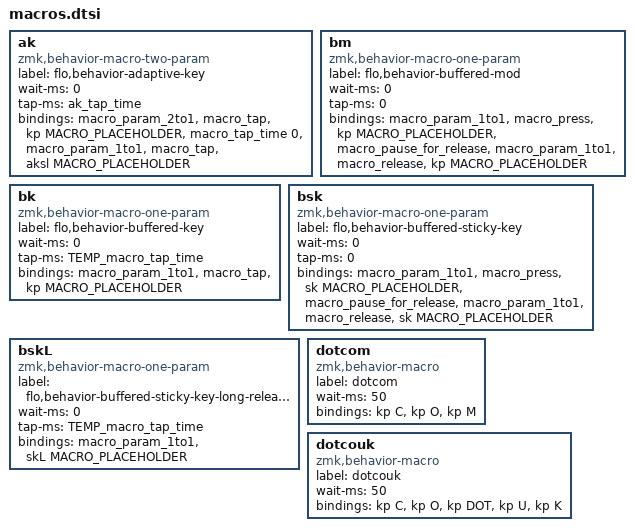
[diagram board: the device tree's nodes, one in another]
REPLACE_CHAR_WITH_BIGRAM(B, B)
REPLACE_CHAR_WITH_BIGRAM(B, M)
REPLACE_CHAR_WITH_BIGRAM(D, G)
REPLACE_CHAR_WITH_BIGRAM(I, F)
REPLACE_CHAR_WITH_BIGRAM(L, B)
REPLACE_CHAR_WITH_BIGRAM(L, G)
REPLACE_CHAR_WITH_BIGRAM(L, K)
REPLACE_CHAR_WITH_BIGRAM(L, M)
REPLACE_CHAR_WITH_BIGRAM(L, N)
REPLACE_CHAR_WITH_BIGRAM(L, V)
REPLACE_CHAR_WITH_BIGRAM(N, J)
REPLACE_CHAR_WITH_BIGRAM(N, K)
REPLACE_CHAR_WITH_BIGRAM(N, M)
REPLACE_CHAR_WITH_BIGRAM(N, V)
REPLACE_CHAR_WITH_BIGRAM(O, B)
REPLACE_CHAR_WITH_BIGRAM(P, M)
REPLACE_CHAR_WITH_BIGRAM(S, B)
REPLACE_CHAR_WITH_BIGRAM(S, P)
REPLACE_CHAR_WITH_BIGRAM(U, B)


ak: ak {
        label = "flo,behavior-adaptive-key";
        compatible = "zmk,behavior-macro-two-param";
        #binding-cells = <2>;
        wait-ms = <0>;
        tap-ms = <ak_tap_time>;
        bindings =
                <&macro_param_2to1>,
                <&macro_tap &kp MACRO_PLACEHOLDER>,

                <&macro_tap_time 0>,

                <&macro_param_1to1>,
                <&macro_tap &aksl MACRO_PLACEHOLDER>;
};


/* // Disable this for now. I don't really need the repeat behavior, and it makes linger keys difficult to hit
bk: bk {
        label = "flo,behavior-buffered-key";
        compatible = "zmk,behavior-macro-one-param";
        #binding-cells = <1>;
        wait-ms = <0>;
        tap-ms = <0>; // Unused
        bindings = 
                <&macro_param_1to1>,
                <&macro_press &kp MACRO_PLACEHOLDER>,

                <&macro_pause_for_release>,

                <&macro_param_1to1>,
                <&macro_release &kp MACRO_PLACEHOLDER>
                ;
};
*/
bm: bm {
        label = "flo,behavior-buffered-mod";
        compatible = "zmk,behavior-macro-one-param";
        #binding-cells = <1>;
        wait-ms = <0>;
        tap-ms = <0>; // Unused
        bindings = 
                <&macro_param_1to1>,
                <&macro_press &kp MACRO_PLACEHOLDER>,

                <&macro_pause_for_release>,

                <&macro_param_1to1>,
                <&macro_release &kp MACRO_PLACEHOLDER>
                ;
};

bk: bk {
        label = "flo,behavior-buffered-key";
        compatible = "zmk,behavior-macro-one-param";
        #binding-cells = <1>;
        wait-ms = <0>;
        tap-ms = <TEMP_macro_tap_time>;
        bindings = 
                <&macro_param_1to1>,
                <&macro_tap &kp MACRO_PLACEHOLDER>
                ;
};

bsk: bsk {
        label = "flo,behavior-buffered-sticky-key";
        compatible = "zmk,behavior-macro-one-param";
        #binding-cells = <1>;
        wait-ms = <0>;
        tap-ms = <0>; // Unused
        bindings = 
                <&macro_param_1to1>,
                <&macro_press &sk MACRO_PLACEHOLDER>,

                <&macro_pause_for_release>,

                <&macro_param_1to1>,
                <&macro_release &sk MACRO_PLACEHOLDER>
                ;
};

bskL: bskL {
        label = "flo,behavior-buffered-sticky-key-long-release";
        compatible = "zmk,behavior-macro-one-param";
        #binding-cells = <1>;
        wait-ms = <0>;
        tap-ms = <TEMP_macro_tap_time>;
        bindings = <&macro_param_1to1>,
                <&skL MACRO_PLACEHOLDER>;
};




dotcom: dotcom {
        label = "dotcom";
        compatible = "zmk,behavior-macro";
        #binding-cells = <0>;
        wait-ms = <50>; // need to slow this down for some systems.
        bindings = <&kp C &kp O &kp M> ;
};
dotcouk: dotcouk {
        label = "dotcouk";
        compatible = "zmk,behavior-macro";
        #binding-cells = <0>;
        wait-ms = <50>; // need to slow this down for some systems.
        bindings = <&kp C &kp O &kp DOT &kp U &kp K>;
};
